# CY8C4245AXI_483 register map
File version: 0.1
PSoC 4200
Registers are 32-bit, read-write, no defined reset value unless marked. A register's access mark holds for its fields unless they carry their own. Offsets are from the block's base; lines under a group give offsets from that group; [hi:lo] are bit positions; {n}, {i} and the like mark numbered series; 'fields as' and 'values as' point back to an identical list; <NAME> marks a mode.

## Memory map
0x00000000 RGBFrameTimer
0x00000000 AnimationTimer
0x00000000 SystimeTimer
0x00000000 UART_Debug — Serial Communication Block
0x00000000 SPI_LED — Serial Communication Block
0x00000000 BatterySenseADC — Sequencing SAR ADC
0x00000000 PWM_1
0x400F0002 PRS_1
0x400F0071 IRLedControl

## RGBFrameTimer
Base 0x00000000
0x40050148 COUNTER — Current counter value
0x4005014C CC — Compare / capture value
0x40050150 CC_BUF — Compare / capture buffer value
0x40050154 PERIOD — Period value
0x40050158 PERIOD_BUF — Period buffer value

## IRLedControl
Base 0x400F0071
0x00 IRLedControl_CONTROL_REG 8-bit

## AnimationTimer
Base 0x00000000
0x40050188 COUNTER — Current counter value
0x4005018C CC — Compare / capture value
0x40050190 CC_BUF — Compare / capture buffer value
0x40050194 PERIOD — Period value
0x40050198 PERIOD_BUF — Period buffer value

## SystimeTimer
Base 0x00000000
0x40050108 COUNTER — Current counter value
0x4005010C CC — Compare / capture value
0x40050110 CC_BUF — Compare / capture buffer value
0x40050114 PERIOD — Period value
0x40050118 PERIOD_BUF — Period buffer value

## PRS_1
Base 0x400F0002
0x00 SINGLE_CYCLE_SEED 8-bit — Current seed value
0x20 SINGLE_CYCLE_POLYNOMIAL 8-bit — Current polynomial value
0x40 SINGLE_CYCLE_COPY 8-bit — Copy seed value

## PWM_1
Base 0x00000000
0x400F0023 PWM_1_COMPARE_Reg_ 8-bit — UDB.D0 - Assigned Compare Value
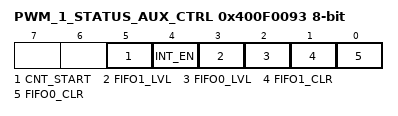
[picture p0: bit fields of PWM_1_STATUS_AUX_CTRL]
0x400F0093 PWM_1_STATUS_AUX_CTRL 8-bit — UDB Auxilliary Control Register
  [5] CNT_START — FIFO0 clear
    0=E_CNT_START0 (Disable counter); 1=E_CNT_START1 (Enable counter)
  [4] INT_EN
    0=E_INT_EN0 (Interrupt disabled); 1=E_INT_EN1 (Interrupt enabled)
  [3] FIFO1_LVL — FIFO level
    0=E_FIFO_LVL_0 (FIFO LVL: input mode: FIFO not full; output mode: FIFO not empty); 1=E_FIFO_LVL_1 (FIFO LVL: input mode: FIFO at least 1/2 empty; output mode: FIFO at least 1/2 full)
  [2] FIFO0_LVL — FIFO level
    values as FIFO1_LVL
  [1] FIFO1_CLR — FIFO1 clear
    0=E_FIFO_CLR_0 (Normal FIFO operation); 1=E_FIFO_CLR_1 (Clear FIFO state)
  [0] FIFO0_CLR — FIFO0 clear
    values as FIFO1_CLR
